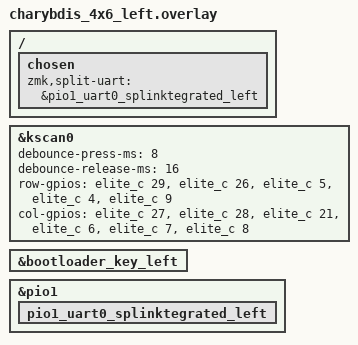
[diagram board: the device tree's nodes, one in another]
#include "charybdis_4x6.dtsi"

&kscan0 {
    debounce-press-ms = <8>;
    debounce-release-ms = <16>;
    row-gpios
        = <&elite_c 29 GPIO_ACTIVE_HIGH>
        , <&elite_c 26 GPIO_ACTIVE_HIGH>
        , <&elite_c  5 GPIO_ACTIVE_HIGH>
        , <&elite_c  4 GPIO_ACTIVE_HIGH>
        , <&elite_c  9 GPIO_ACTIVE_HIGH>
        ;

    col-gpios
        = <&elite_c 27 (GPIO_PULL_DOWN | GPIO_ACTIVE_HIGH)>
        , <&elite_c 28 (GPIO_PULL_DOWN | GPIO_ACTIVE_HIGH)>
        , <&elite_c 21 (GPIO_PULL_DOWN | GPIO_ACTIVE_HIGH)>
        , <&elite_c  6 (GPIO_PULL_DOWN | GPIO_ACTIVE_HIGH)>
        , <&elite_c  7 (GPIO_PULL_DOWN | GPIO_ACTIVE_HIGH)>
        , <&elite_c  8 (GPIO_PULL_DOWN | GPIO_ACTIVE_HIGH)>
        ;
};

&bootloader_key_left {
    status = "okay";
};

/ {
	chosen {
        zmk,split-uart = &pio1_uart0_splinktegrated_left;
	};
};

&pio1 {
	pio1_uart0_splinktegrated_left: pio1_uart0_splinktegrated_left {
		status = "okay";
	};
};
